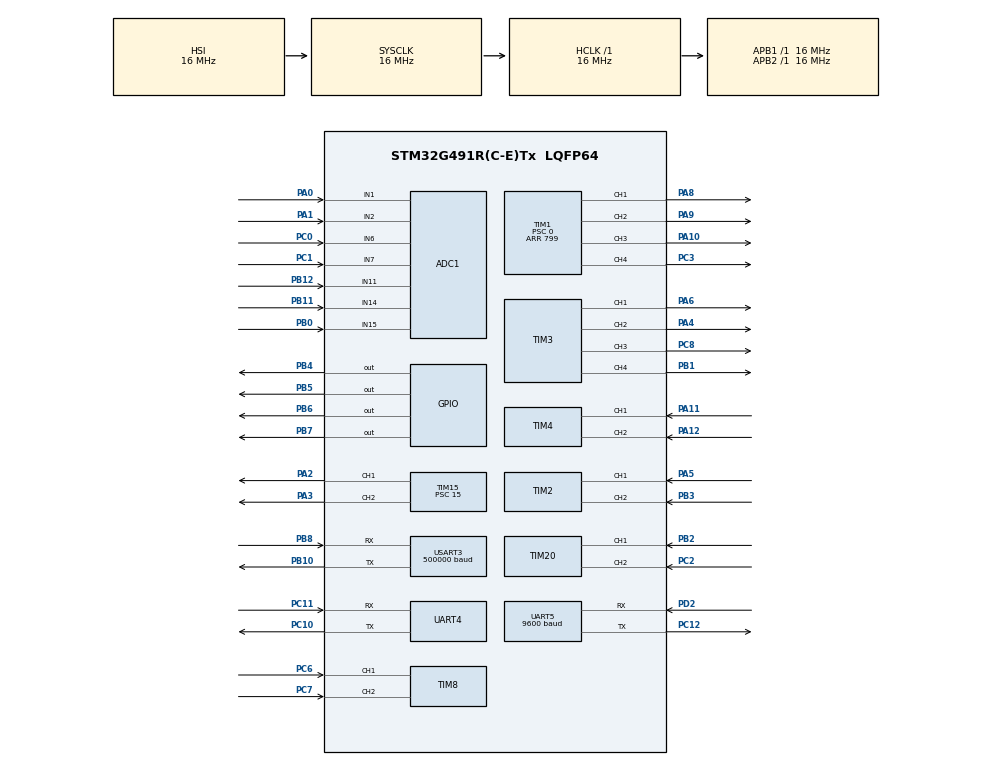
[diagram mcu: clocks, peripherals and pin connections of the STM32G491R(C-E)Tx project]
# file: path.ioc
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ADC1.Channel-1\#ChannelRegularConversion=ADC_CHANNEL_1
ADC1.Channel-2\#ChannelRegularConversion=ADC_CHANNEL_2
ADC1.Channel-3\#ChannelRegularConversion=ADC_CHANNEL_15
ADC1.Channel-4\#ChannelRegularConversion=ADC_CHANNEL_7
ADC1.Channel-5\#ChannelRegularConversion=ADC_CHANNEL_6
ADC1.Channel-6\#ChannelRegularConversion=ADC_CHANNEL_11
ADC1.Channel-7\#ChannelRegularConversion=ADC_CHANNEL_14
ADC1.ContinuousConvMode=ENABLE
ADC1.DMAContinuousRequests=ENABLE
ADC1.NbrOfConversion=7
ADC1.NbrOfConversionFlag=1
ADC1.OffsetNumber-1\#ChannelRegularConversion=ADC_OFFSET_NONE
ADC1.OffsetNumber-2\#ChannelRegularConversion=ADC_OFFSET_NONE
ADC1.OffsetNumber-3\#ChannelRegularConversion=ADC_OFFSET_NONE
ADC1.OffsetNumber-4\#ChannelRegularConversion=ADC_OFFSET_NONE
ADC1.OffsetNumber-5\#ChannelRegularConversion=ADC_OFFSET_NONE
ADC1.OffsetNumber-6\#ChannelRegularConversion=ADC_OFFSET_NONE
ADC1.OffsetNumber-7\#ChannelRegularConversion=ADC_OFFSET_NONE
ADC1.Rank-1\#ChannelRegularConversion=1
ADC1.Rank-2\#ChannelRegularConversion=2
ADC1.Rank-3\#ChannelRegularConversion=3
ADC1.Rank-4\#ChannelRegularConversion=4
ADC1.Rank-5\#ChannelRegularConversion=5
ADC1.Rank-6\#ChannelRegularConversion=6
ADC1.Rank-7\#ChannelRegularConversion=7
ADC1.SamplingTime-1\#ChannelRegularConversion=ADC_SAMPLETIME_92CYCLES_5
ADC1.SamplingTime-2\#ChannelRegularConversion=ADC_SAMPLETIME_92CYCLES_5
ADC1.SamplingTime-3\#ChannelRegularConversion=ADC_SAMPLETIME_92CYCLES_5
ADC1.SamplingTime-4\#ChannelRegularConversion=ADC_SAMPLETIME_92CYCLES_5
ADC1.SamplingTime-5\#ChannelRegularConversion=ADC_SAMPLETIME_92CYCLES_5
ADC1.SamplingTime-6\#ChannelRegularConversion=ADC_SAMPLETIME_92CYCLES_5
ADC1.SamplingTime-7\#ChannelRegularConversion=ADC_SAMPLETIME_92CYCLES_5
ADC1.master=1
Dma.ADC1.0.Direction=DMA_PERIPH_TO_MEMORY
Dma.ADC1.0.EventEnable=DISABLE
Dma.ADC1.0.Instance=DMA1_Channel3
Dma.ADC1.0.MemDataAlignment=DMA_MDATAALIGN_HALFWORD
Dma.ADC1.0.MemInc=DMA_MINC_ENABLE
Dma.ADC1.0.Mode=DMA_CIRCULAR
Dma.ADC1.0.PeriphDataAlignment=DMA_PDATAALIGN_HALFWORD
Dma.ADC1.0.PeriphInc=DMA_PINC_DISABLE
Dma.ADC1.0.Polarity=HAL_DMAMUX_REQ_GEN_RISING
Dma.ADC1.0.Priority=DMA_PRIORITY_LOW
Dma.ADC1.0.RequestNumber=1
Dma.ADC1.0.SignalID=NONE
Dma.ADC1.0.SyncEnable=DISABLE
Dma.ADC1.0.SyncPolarity=HAL_DMAMUX_SYNC_NO_EVENT
Dma.ADC1.0.SyncRequestNumber=1
Dma.ADC1.0.SyncSignalID=NONE
Dma.Request0=ADC1
Mcu.Family=STM32G4
Mcu.Name=STM32G491R(C-E)Tx
Mcu.Package=LQFP64
NVIC.DMA1_Channel3_IRQn=true\:0\:0\:false\:false\:true\:false\:true\:true
NVIC.PriorityGroup=NVIC_PRIORITYGROUP_4
NVIC.TIM1_BRK_TIM15_IRQn=true\:0\:0\:false\:false\:true\:true\:true\:true
NVIC.TIM3_IRQn=true\:0\:0\:false\:false\:true\:true\:true\:true
NVIC.TIM6_DAC_IRQn=true\:0\:0\:false\:false\:true\:true\:true\:true
NVIC.UART5_IRQn=true\:0\:0\:false\:false\:true\:true\:true\:true
PA0.Mode=IN1-Single-Ended
PA0.Signal=ADC1_IN1
PA1.Mode=IN2-Single-Ended
PA1.Signal=ADC1_IN2
PA10.Signal=S_TIM1_CH3
PA11.Signal=S_TIM4_CH1
PA12.Signal=S_TIM4_CH2
PA2.Signal=S_TIM15_CH1
PA3.Signal=S_TIM15_CH2
PA4.Signal=S_TIM3_CH2
PA5.Signal=S_TIM2_CH1
PA6.Signal=S_TIM3_CH1
PA8.Signal=S_TIM1_CH1
PA9.Signal=S_TIM1_CH2
PB0.Mode=IN15-Single-Ended
PB0.Signal=ADC1_IN15
PB1.Signal=S_TIM3_CH4
PB10.Mode=Asynchronous
PB10.Signal=USART3_TX
PB11.Mode=IN14-Single-Ended
PB11.Signal=ADC1_IN14
PB12.Mode=IN11-Single-Ended
PB12.Signal=ADC1_IN11
PB2.Mode=Encoder_Interface
PB2.Signal=TIM20_CH1
PB3.Signal=S_TIM2_CH2
PB4.Signal=GPIO_Output
PB5.Signal=GPIO_Output
PB6.Signal=GPIO_Output
PB7.Signal=GPIO_Output
PB8-BOOT0.Mode=Asynchronous
PB8-BOOT0.Signal=USART3_RX
PC0.Mode=IN6-Single-Ended
PC0.Signal=ADC1_IN6
PC1.Mode=IN7-Single-Ended
PC1.Signal=ADC1_IN7
PC10.Mode=Asynchronous
PC10.Signal=UART4_TX
PC11.Mode=Asynchronous
PC11.Signal=UART4_RX
PC12.Mode=Asynchronous
PC12.Signal=UART5_TX
PC2.Signal=S_TIM20_CH2
PC3.Signal=S_TIM1_CH4
PC6.Signal=S_TIM8_CH1
PC7.Signal=S_TIM8_CH2
PC8.Signal=S_TIM3_CH3
PD2.Mode=Asynchronous
PD2.Signal=UART5_RX
ProjectManager.HeapSize=0x200
ProjectManager.StackSize=0x400
ProjectManager.TargetToolchain=STM32CubeIDE
RCC.ADC12Freq_Value=16000000
RCC.ADC345Freq_Value=16000000
RCC.AHBFreq_Value=16000000
RCC.APB1Freq_Value=16000000
RCC.APB1TimFreq_Value=16000000
RCC.APB2Freq_Value=16000000
RCC.APB2TimFreq_Value=16000000
RCC.CortexFreq_Value=16000000
RCC.EXTERNAL_CLOCK_VALUE=12288000
RCC.HCLKFreq_Value=16000000
RCC.HSE_VALUE=8000000
RCC.HSI48_VALUE=48000000
RCC.HSI_VALUE=16000000
RCC.LSE_VALUE=32768
RCC.SYSCLKFreq_VALUE=16000000
RCC.USBFreq_Value=48000000
RCC.VCOOutputFreq_Value=128000000
SH.S_TIM15_CH1.0=TIM15_CH1,PWM Generation1 CH1
SH.S_TIM15_CH2.0=TIM15_CH2,PWM Generation2 CH2
SH.S_TIM1_CH1.0=TIM1_CH1,PWM Generation1 CH1
SH.S_TIM1_CH2.0=TIM1_CH2,PWM Generation2 CH2
SH.S_TIM1_CH3.0=TIM1_CH3,PWM Generation3 CH3
SH.S_TIM1_CH4.0=TIM1_CH4,PWM Generation4 CH4
SH.S_TIM20_CH2.0=TIM20_CH2,Encoder_Interface
SH.S_TIM2_CH1.0=TIM2_CH1,Encoder_Interface
SH.S_TIM2_CH2.0=TIM2_CH2,Encoder_Interface
SH.S_TIM3_CH1.0=TIM3_CH1,PWM Generation1 CH1
SH.S_TIM3_CH2.0=TIM3_CH2,PWM Generation2 CH2
SH.S_TIM3_CH3.0=TIM3_CH3,PWM Generation3 CH3
SH.S_TIM3_CH4.0=TIM3_CH4,PWM Generation4 CH4
SH.S_TIM4_CH1.0=TIM4_CH1,Encoder_Interface
SH.S_TIM4_CH2.0=TIM4_CH2,Encoder_Interface
SH.S_TIM8_CH1.0=TIM8_CH1,Encoder_Interface
SH.S_TIM8_CH2.0=TIM8_CH2,Encoder_Interface
TIM1.Channel-PWM\ Generation1\ CH1=TIM_CHANNEL_1
TIM1.Channel-PWM\ Generation2\ CH2=TIM_CHANNEL_2
TIM1.Channel-PWM\ Generation3\ CH3=TIM_CHANNEL_3
TIM1.Channel-PWM\ Generation4\ CH4=TIM_CHANNEL_4
TIM1.PeriodNoDither=799
TIM1.Prescaler=0
TIM15.Channel-PWM\ Generation1\ CH1=TIM_CHANNEL_1
TIM15.Channel-PWM\ Generation2\ CH2=TIM_CHANNEL_2
TIM15.PeriodNoDither=19999
TIM15.Prescaler=15
TIM3.Channel-PWM\ Generation1\ CH1=TIM_CHANNEL_1
TIM3.Channel-PWM\ Generation2\ CH2=TIM_CHANNEL_2
TIM3.Channel-PWM\ Generation3\ CH3=TIM_CHANNEL_3
TIM3.Channel-PWM\ Generation4\ CH4=TIM_CHANNEL_4
TIM6.PeriodNoDither=999
TIM6.Prescaler=15
TIM8.EncoderMode=TIM_ENCODERMODE_TI12
UART5.BaudRate=9600
USART3.BaudRate=500000
USART3.VirtualMode-Asynchronous=VM_ASYNC
VP_TIM16_VS_ClockSourceINT.Mode=Enable_Timer
VP_TIM6_VS_ClockSourceINT.Mode=Enable_Timer
board=custom

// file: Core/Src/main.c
/* USER CODE BEGIN Header */
/**
  ******************************************************************************
  * @file           : main.c
  * @brief          : Main program body
  ******************************************************************************
  * @attention
  *
  * Copyright (c) 2024 STMicroelectronics.
  * All rights reserved.
  *
  * This software is licensed under terms that can be found in the LICENSE file
  * in the root directory of this software component.
  * If no LICENSE file comes with this software, it is provided AS-IS.
  *
  ******************************************************************************
  */
/* USER CODE END Header */
#include "main.h"

/* USER CODE BEGIN Includes */
#include "mainpp.h"
/* USER CODE END Includes */

ADC_HandleTypeDef hadc1;
DMA_HandleTypeDef hdma_adc1;

TIM_HandleTypeDef htim1;
TIM_HandleTypeDef htim2;
TIM_HandleTypeDef htim3;
TIM_HandleTypeDef htim4;
TIM_HandleTypeDef htim6;
TIM_HandleTypeDef htim8;
TIM_HandleTypeDef htim15;
TIM_HandleTypeDef htim16;
TIM_HandleTypeDef htim20;

UART_HandleTypeDef huart4;
UART_HandleTypeDef huart5;
UART_HandleTypeDef huart3;

void SystemClock_Config(void);
static void MX_GPIO_Init(void);
static void MX_DMA_Init(void);
static void MX_ADC1_Init(void);
static void MX_TIM6_Init(void);
static void MX_TIM15_Init(void);
static void MX_TIM4_Init(void);
static void MX_UART5_Init(void);
static void MX_TIM3_Init(void);
static void MX_TIM1_Init(void);
static void MX_TIM8_Init(void);
static void MX_TIM16_Init(void);
static void MX_TIM20_Init(void);
static void MX_UART4_Init(void);
static void MX_USART3_UART_Init(void);
static void MX_TIM2_Init(void);

int main(void)
{

  /* MCU Configuration--------------------------------------------------------*/

  /* Reset of all peripherals, Initializes the Flash interface and the Systick. */
  HAL_Init();

  /* Configure the system clock */
  SystemClock_Config();

  /* Initialize all configured peripherals */
  MX_GPIO_Init();
  MX_DMA_Init();
  MX_ADC1_Init();
  MX_TIM6_Init();
  MX_TIM15_Init();
  MX_TIM4_Init();
  MX_UART5_Init();
  MX_TIM3_Init();
  MX_TIM1_Init();
  MX_TIM8_Init();
  MX_TIM16_Init();
  MX_TIM20_Init();
  MX_UART4_Init();
  MX_USART3_UART_Init();
  MX_TIM2_Init();
  /* USER CODE BEGIN 2 */
  //
  setup();
  /* USER CODE END 2 */

  /* Infinite loop */
  /* USER CODE BEGIN WHILE */
  while (1)
  {main_function();
    /* USER CODE END WHILE */

  }
}

void SystemClock_Config(void)
{
  RCC_OscInitTypeDef RCC_OscInitStruct = {0};
  RCC_ClkInitTypeDef RCC_ClkInitStruct = {0};

  /** Configure the main internal regulator output voltage
  */
  HAL_PWREx_ControlVoltageScaling(PWR_REGULATOR_VOLTAGE_SCALE1);

  /** Initializes the RCC Oscillators according to the specified parameters
  * in the RCC_OscInitTypeDef structure.
  */
  RCC_OscInitStruct.OscillatorType = RCC_OSCILLATORTYPE_HSI;
  RCC_OscInitStruct.HSIState = RCC_HSI_ON;
  RCC_OscInitStruct.HSICalibrationValue = RCC_HSICALIBRATION_DEFAULT;
  RCC_OscInitStruct.PLL.PLLState = RCC_PLL_NONE;
  if (HAL_RCC_OscConfig(&RCC_OscInitStruct) != HAL_OK)
  {
    Error_Handler();
  }

  /** Initializes the CPU, AHB and APB buses clocks
  */
  RCC_ClkInitStruct.ClockType = RCC_CLOCKTYPE_HCLK|RCC_CLOCKTYPE_SYSCLK
                              |RCC_CLOCKTYPE_PCLK1|RCC_CLOCKTYPE_PCLK2;
  RCC_ClkInitStruct.SYSCLKSource = RCC_SYSCLKSOURCE_HSI;
  RCC_ClkInitStruct.AHBCLKDivider = RCC_SYSCLK_DIV1;
  RCC_ClkInitStruct.APB1CLKDivider = RCC_HCLK_DIV1;
  RCC_ClkInitStruct.APB2CLKDivider = RCC_HCLK_DIV1;

  if (HAL_RCC_ClockConfig(&RCC_ClkInitStruct, FLASH_LATENCY_0) != HAL_OK)
  {
    Error_Handler();
  }
}

static void MX_ADC1_Init(void)
{

  ADC_MultiModeTypeDef multimode = {0};
  ADC_ChannelConfTypeDef sConfig = {0};

  /** Common config
  */
  hadc1.Instance = ADC1;
  hadc1.Init.ClockPrescaler = ADC_CLOCK_SYNC_PCLK_DIV2;
  hadc1.Init.Resolution = ADC_RESOLUTION_12B;
  hadc1.Init.DataAlign = ADC_DATAALIGN_RIGHT;
  hadc1.Init.GainCompensation = 0;
  hadc1.Init.ScanConvMode = ADC_SCAN_ENABLE;
  hadc1.Init.EOCSelection = ADC_EOC_SINGLE_CONV;
  hadc1.Init.LowPowerAutoWait = DISABLE;
  hadc1.Init.ContinuousConvMode = ENABLE;
  hadc1.Init.NbrOfConversion = 7;
  hadc1.Init.DiscontinuousConvMode = DISABLE;
  hadc1.Init.ExternalTrigConv = ADC_SOFTWARE_START;
  hadc1.Init.ExternalTrigConvEdge = ADC_EXTERNALTRIGCONVEDGE_NONE;
  hadc1.Init.DMAContinuousRequests = ENABLE;
  hadc1.Init.Overrun = ADC_OVR_DATA_PRESERVED;
  hadc1.Init.OversamplingMode = DISABLE;
  if (HAL_ADC_Init(&hadc1) != HAL_OK)
  {
    Error_Handler();
  }

  /** Configure the ADC multi-mode
  */
  multimode.Mode = ADC_MODE_INDEPENDENT;
  if (HAL_ADCEx_MultiModeConfigChannel(&hadc1, &multimode) != HAL_OK)
  {
    Error_Handler();
  }

  /** Configure Regular Channel
  */
  sConfig.Channel = ADC_CHANNEL_1;
  sConfig.Rank = ADC_REGULAR_RANK_1;
  sConfig.SamplingTime = ADC_SAMPLETIME_92CYCLES_5;
  sConfig.SingleDiff = ADC_SINGLE_ENDED;
  sConfig.OffsetNumber = ADC_OFFSET_NONE;
  sConfig.Offset = 0;
  if (HAL_ADC_ConfigChannel(&hadc1, &sConfig) != HAL_OK)
  {
    Error_Handler();
  }

  /** Configure Regular Channel
  */
  sConfig.Channel = ADC_CHANNEL_2;
  sConfig.Rank = ADC_REGULAR_RANK_2;
  if (HAL_ADC_ConfigChannel(&hadc1, &sConfig) != HAL_OK)
  {
    Error_Handler();
  }

  /** Configure Regular Channel
  */
  sConfig.Channel = ADC_CHANNEL_15;
  sConfig.Rank = ADC_REGULAR_RANK_3;
  if (HAL_ADC_ConfigChannel(&hadc1, &sConfig) != HAL_OK)
  {
    Error_Handler();
  }

  /** Configure Regular Channel
  */
  sConfig.Channel = ADC_CHANNEL_7;
  sConfig.Rank = ADC_REGULAR_RANK_4;
  if (HAL_ADC_ConfigChannel(&hadc1, &sConfig) != HAL_OK)
  {
    Error_Handler();
  }

  /** Configure Regular Channel
  */
  sConfig.Channel = ADC_CHANNEL_6;
  sConfig.Rank = ADC_REGULAR_RANK_5;
  if (HAL_ADC_ConfigChannel(&hadc1, &sConfig) != HAL_OK)
  {
    Error_Handler();
  }

  /** Configure Regular Channel
  */
  sConfig.Channel = ADC_CHANNEL_11;
  sConfig.Rank = ADC_REGULAR_RANK_6;
  if (HAL_ADC_ConfigChannel(&hadc1, &sConfig) != HAL_OK)
  {
    Error_Handler();
  }

  /** Configure Regular Channel
  */
  sConfig.Channel = ADC_CHANNEL_14;
  sConfig.Rank = ADC_REGULAR_RANK_7;
  if (HAL_ADC_ConfigChannel(&hadc1, &sConfig) != HAL_OK)
  {
    Error_Handler();
  }

}

static void MX_TIM1_Init(void)
{

  TIM_MasterConfigTypeDef sMasterConfig = {0};
  TIM_OC_InitTypeDef sConfigOC = {0};
  TIM_BreakDeadTimeConfigTypeDef sBreakDeadTimeConfig = {0};

  htim1.Instance = TIM1;
  htim1.Init.Prescaler = 0;
  htim1.Init.CounterMode = TIM_COUNTERMODE_UP;
  htim1.Init.Period = 799;
  htim1.Init.ClockDivision = TIM_CLOCKDIVISION_DIV1;
  htim1.Init.RepetitionCounter = 0;
  htim1.Init.AutoReloadPreload = TIM_AUTORELOAD_PRELOAD_DISABLE;
  if (HAL_TIM_PWM_Init(&htim1) != HAL_OK)
  {
    Error_Handler();
  }
  sMasterConfig.MasterOutputTrigger = TIM_TRGO_RESET;
  sMasterConfig.MasterOutputTrigger2 = TIM_TRGO2_RESET;
  sMasterConfig.MasterSlaveMode = TIM_MASTERSLAVEMODE_DISABLE;
  if (HAL_TIMEx_MasterConfigSynchronization(&htim1, &sMasterConfig) != HAL_OK)
  {
    Error_Handler();
  }
  sConfigOC.OCMode = TIM_OCMODE_PWM1;
  sConfigOC.Pulse = 0;
  sConfigOC.OCPolarity = TIM_OCPOLARITY_HIGH;
  sConfigOC.OCNPolarity = TIM_OCNPOLARITY_HIGH;
  sConfigOC.OCFastMode = TIM_OCFAST_DISABLE;
  sConfigOC.OCIdleState = TIM_OCIDLESTATE_RESET;
  sConfigOC.OCNIdleState = TIM_OCNIDLESTATE_RESET;
  if (HAL_TIM_PWM_ConfigChannel(&htim1, &sConfigOC, TIM_CHANNEL_1) != HAL_OK)
  {
    Error_Handler();
  }
  if (HAL_TIM_PWM_ConfigChannel(&htim1, &sConfigOC, TIM_CHANNEL_2) != HAL_OK)
  {
    Error_Handler();
  }
  if (HAL_TIM_PWM_ConfigChannel(&htim1, &sConfigOC, TIM_CHANNEL_3) != HAL_OK)
  {
    Error_Handler();
  }
  if (HAL_TIM_PWM_ConfigChannel(&htim1, &sConfigOC, TIM_CHANNEL_4) != HAL_OK)
  {
    Error_Handler();
  }
  sBreakDeadTimeConfig.OffStateRunMode = TIM_OSSR_DISABLE;
  sBreakDeadTimeConfig.OffStateIDLEMode = TIM_OSSI_DISABLE;
  sBreakDeadTimeConfig.LockLevel = TIM_LOCKLEVEL_OFF;
  sBreakDeadTimeConfig.DeadTime = 0;
  sBreakDeadTimeConfig.BreakState = TIM_BREAK_DISABLE;
  sBreakDeadTimeConfig.BreakPolarity = TIM_BREAKPOLARITY_HIGH;
  sBreakDeadTimeConfig.BreakFilter = 0;
  sBreakDeadTimeConfig.BreakAFMode = TIM_BREAK_AFMODE_INPUT;
  sBreakDeadTimeConfig.Break2State = TIM_BREAK2_DISABLE;
  sBreakDeadTimeConfig.Break2Polarity = TIM_BREAK2POLARITY_HIGH;
  sBreakDeadTimeConfig.Break2Filter = 0;
  sBreakDeadTimeConfig.Break2AFMode = TIM_BREAK_AFMODE_INPUT;
  sBreakDeadTimeConfig.AutomaticOutput = TIM_AUTOMATICOUTPUT_DISABLE;
  if (HAL_TIMEx_ConfigBreakDeadTime(&htim1, &sBreakDeadTimeConfig) != HAL_OK)
  {
    Error_Handler();
  }
  HAL_TIM_MspPostInit(&htim1);

}

static void MX_TIM2_Init(void)
{

  TIM_Encoder_InitTypeDef sConfig = {0};
  TIM_MasterConfigTypeDef sMasterConfig = {0};

  htim2.Instance = TIM2;
  htim2.Init.Prescaler = 0;
  htim2.Init.CounterMode = TIM_COUNTERMODE_UP;
  htim2.Init.Period = 4.294967295E9;
  htim2.Init.ClockDivision = TIM_CLOCKDIVISION_DIV1;
  htim2.Init.AutoReloadPreload = TIM_AUTORELOAD_PRELOAD_DISABLE;
  sConfig.EncoderMode = TIM_ENCODERMODE_TI1;
  sConfig.IC1Polarity = TIM_ICPOLARITY_RISING;
  sConfig.IC1Selection = TIM_ICSELECTION_DIRECTTI;
  sConfig.IC1Prescaler = TIM_ICPSC_DIV1;
  sConfig.IC1Filter = 0;
  sConfig.IC2Polarity = TIM_ICPOLARITY_RISING;
  sConfig.IC2Selection = TIM_ICSELECTION_DIRECTTI;
  sConfig.IC2Prescaler = TIM_ICPSC_DIV1;
  sConfig.IC2Filter = 0;
  if (HAL_TIM_Encoder_Init(&htim2, &sConfig) != HAL_OK)
  {
    Error_Handler();
  }
  sMasterConfig.MasterOutputTrigger = TIM_TRGO_RESET;
  sMasterConfig.MasterSlaveMode = TIM_MASTERSLAVEMODE_DISABLE;
  if (HAL_TIMEx_MasterConfigSynchronization(&htim2, &sMasterConfig) != HAL_OK)
  {
    Error_Handler();
  }

}

static void MX_TIM3_Init(void)
{

  TIM_MasterConfigTypeDef sMasterConfig = {0};
  TIM_OC_InitTypeDef sConfigOC = {0};

  htim3.Instance = TIM3;
  htim3.Init.Prescaler = 0;
  htim3.Init.CounterMode = TIM_COUNTERMODE_UP;
  htim3.Init.Period = 65535;
  htim3.Init.ClockDivision = TIM_CLOCKDIVISION_DIV1;
  htim3.Init.AutoReloadPreload = TIM_AUTORELOAD_PRELOAD_DISABLE;
  if (HAL_TIM_PWM_Init(&htim3) != HAL_OK)
  {
    Error_Handler();
  }
  sMasterConfig.MasterOutputTrigger = TIM_TRGO_RESET;
  sMasterConfig.MasterSlaveMode = TIM_MASTERSLAVEMODE_DISABLE;
  if (HAL_TIMEx_MasterConfigSynchronization(&htim3, &sMasterConfig) != HAL_OK)
  {
    Error_Handler();
  }
  sConfigOC.OCMode = TIM_OCMODE_PWM1;
  sConfigOC.Pulse = 0;
  sConfigOC.OCPolarity = TIM_OCPOLARITY_HIGH;
  sConfigOC.OCFastMode = TIM_OCFAST_DISABLE;
  if (HAL_TIM_PWM_ConfigChannel(&htim3, &sConfigOC, TIM_CHANNEL_1) != HAL_OK)
  {
    Error_Handler();
  }
  if (HAL_TIM_PWM_ConfigChannel(&htim3, &sConfigOC, TIM_CHANNEL_2) != HAL_OK)
  {
    Error_Handler();
  }
  if (HAL_TIM_PWM_ConfigChannel(&htim3, &sConfigOC, TIM_CHANNEL_3) != HAL_OK)
  {
    Error_Handler();
  }
  if (HAL_TIM_PWM_ConfigChannel(&htim3, &sConfigOC, TIM_CHANNEL_4) != HAL_OK)
  {
    Error_Handler();
  }
  HAL_TIM_MspPostInit(&htim3);

}

static void MX_TIM4_Init(void)
{

  TIM_Encoder_InitTypeDef sConfig = {0};
  TIM_MasterConfigTypeDef sMasterConfig = {0};

  htim4.Instance = TIM4;
  htim4.Init.Prescaler = 0;
  htim4.Init.CounterMode = TIM_COUNTERMODE_UP;
  htim4.Init.Period = 65535;
  htim4.Init.ClockDivision = TIM_CLOCKDIVISION_DIV1;
  htim4.Init.AutoReloadPreload = TIM_AUTORELOAD_PRELOAD_DISABLE;
  sConfig.EncoderMode = TIM_ENCODERMODE_TI1;
  sConfig.IC1Polarity = TIM_ICPOLARITY_RISING;
  sConfig.IC1Selection = TIM_ICSELECTION_DIRECTTI;
  sConfig.IC1Prescaler = TIM_ICPSC_DIV1;
  sConfig.IC1Filter = 0;
  sConfig.IC2Polarity = TIM_ICPOLARITY_RISING;
  sConfig.IC2Selection = TIM_ICSELECTION_DIRECTTI;
  sConfig.IC2Prescaler = TIM_ICPSC_DIV1;
  sConfig.IC2Filter = 0;
  if (HAL_TIM_Encoder_Init(&htim4, &sConfig) != HAL_OK)
  {
    Error_Handler();
  }
  sMasterConfig.MasterOutputTrigger = TIM_TRGO_RESET;
  sMasterConfig.MasterSlaveMode = TIM_MASTERSLAVEMODE_DISABLE;
  if (HAL_TIMEx_MasterConfigSynchronization(&htim4, &sMasterConfig) != HAL_OK)
  {
    Error_Handler();
  }

}

static void MX_TIM6_Init(void)
{

  TIM_MasterConfigTypeDef sMasterConfig = {0};

  htim6.Instance = TIM6;
  htim6.Init.Prescaler = 15;
  htim6.Init.CounterMode = TIM_COUNTERMODE_UP;
  htim6.Init.Period = 999;
  htim6.Init.AutoReloadPreload = TIM_AUTORELOAD_PRELOAD_DISABLE;
  if (HAL_TIM_Base_Init(&htim6) != HAL_OK)
  {
    Error_Handler();
  }
  sMasterConfig.MasterOutputTrigger = TIM_TRGO_RESET;
  sMasterConfig.MasterSlaveMode = TIM_MASTERSLAVEMODE_DISABLE;
  if (HAL_TIMEx_MasterConfigSynchronization(&htim6, &sMasterConfig) != HAL_OK)
  {
    Error_Handler();
  }

}

static void MX_TIM8_Init(void)
{

  TIM_Encoder_InitTypeDef sConfig = {0};
  TIM_MasterConfigTypeDef sMasterConfig = {0};

  htim8.Instance = TIM8;
  htim8.Init.Prescaler = 0;
  htim8.Init.CounterMode = TIM_COUNTERMODE_UP;
  htim8.Init.Period = 65535;
  htim8.Init.ClockDivision = TIM_CLOCKDIVISION_DIV1;
  htim8.Init.RepetitionCounter = 0;
  htim8.Init.AutoReloadPreload = TIM_AUTORELOAD_PRELOAD_DISABLE;
  sConfig.EncoderMode = TIM_ENCODERMODE_TI12;
  sConfig.IC1Polarity = TIM_ICPOLARITY_RISING;
  sConfig.IC1Selection = TIM_ICSELECTION_DIRECTTI;
  sConfig.IC1Prescaler = TIM_ICPSC_DIV1;
  sConfig.IC1Filter = 0;
  sConfig.IC2Polarity = TIM_ICPOLARITY_RISING;
  sConfig.IC2Selection = TIM_ICSELECTION_DIRECTTI;
  sConfig.IC2Prescaler = TIM_ICPSC_DIV1;
  sConfig.IC2Filter = 0;
  if (HAL_TIM_Encoder_Init(&htim8, &sConfig) != HAL_OK)
  {
    Error_Handler();
  }
  sMasterConfig.MasterOutputTrigger = TIM_TRGO_RESET;
  sMasterConfig.MasterOutputTrigger2 = TIM_TRGO2_RESET;
  sMasterConfig.MasterSlaveMode = TIM_MASTERSLAVEMODE_DISABLE;
  if (HAL_TIMEx_MasterConfigSynchronization(&htim8, &sMasterConfig) != HAL_OK)
  {
    Error_Handler();
  }

}

static void MX_TIM15_Init(void)
{

  TIM_MasterConfigTypeDef sMasterConfig = {0};
  TIM_OC_InitTypeDef sConfigOC = {0};
  TIM_BreakDeadTimeConfigTypeDef sBreakDeadTimeConfig = {0};

  htim15.Instance = TIM15;
  htim15.Init.Prescaler = 15;
  htim15.Init.CounterMode = TIM_COUNTERMODE_UP;
  htim15.Init.Period = 19999;
  htim15.Init.ClockDivision = TIM_CLOCKDIVISION_DIV1;
  htim15.Init.RepetitionCounter = 0;
  htim15.Init.AutoReloadPreload = TIM_AUTORELOAD_PRELOAD_DISABLE;
  if (HAL_TIM_PWM_Init(&htim15) != HAL_OK)
  {
    Error_Handler();
  }
  sMasterConfig.MasterOutputTrigger = TIM_TRGO_RESET;
  sMasterConfig.MasterSlaveMode = TIM_MASTERSLAVEMODE_DISABLE;
  if (HAL_TIMEx_MasterConfigSynchronization(&htim15, &sMasterConfig) != HAL_OK)
  {
    Error_Handler();
  }
  sConfigOC.OCMode = TIM_OCMODE_PWM1;
  sConfigOC.Pulse = 0;
  sConfigOC.OCPolarity = TIM_OCPOLARITY_HIGH;
  sConfigOC.OCNPolarity = TIM_OCNPOLARITY_HIGH;
  sConfigOC.OCFastMode = TIM_OCFAST_DISABLE;
  sConfigOC.OCIdleState = TIM_OCIDLESTATE_RESET;
  sConfigOC.OCNIdleState = TIM_OCNIDLESTATE_RESET;
  if (HAL_TIM_PWM_ConfigChannel(&htim15, &sConfigOC, TIM_CHANNEL_1) != HAL_OK)
  {
    Error_Handler();
  }
  if (HAL_TIM_PWM_ConfigChannel(&htim15, &sConfigOC, TIM_CHANNEL_2) != HAL_OK)
  {
    Error_Handler();
  }
  sBreakDeadTimeConfig.OffStateRunMode = TIM_OSSR_DISABLE;
  sBreakDeadTimeConfig.OffStateIDLEMode = TIM_OSSI_DISABLE;
  sBreakDeadTimeConfig.LockLevel = TIM_LOCKLEVEL_OFF;
  sBreakDeadTimeConfig.DeadTime = 0;
  sBreakDeadTimeConfig.BreakState = TIM_BREAK_DISABLE;
  sBreakDeadTimeConfig.BreakPolarity = TIM_BREAKPOLARITY_HIGH;
  sBreakDeadTimeConfig.BreakFilter = 0;
  sBreakDeadTimeConfig.AutomaticOutput = TIM_AUTOMATICOUTPUT_DISABLE;
  if (HAL_TIMEx_ConfigBreakDeadTime(&htim15, &sBreakDeadTimeConfig) != HAL_OK)
  {
    Error_Handler();
  }
  HAL_TIM_MspPostInit(&htim15);

}

static void MX_TIM16_Init(void)
{

  htim16.Instance = TIM16;
  htim16.Init.Prescaler = 0;
  htim16.Init.CounterMode = TIM_COUNTERMODE_UP;
  htim16.Init.Period = 65535;
  htim16.Init.ClockDivision = TIM_CLOCKDIVISION_DIV1;
  htim16.Init.RepetitionCounter = 0;
  htim16.Init.AutoReloadPreload = TIM_AUTORELOAD_PRELOAD_DISABLE;
  if (HAL_TIM_Base_Init(&htim16) != HAL_OK)
  {
    Error_Handler();
  }

}

static void MX_TIM20_Init(void)
{

  TIM_Encoder_InitTypeDef sConfig = {0};
  TIM_MasterConfigTypeDef sMasterConfig = {0};

  htim20.Instance = TIM20;
  htim20.Init.Prescaler = 0;
  htim20.Init.CounterMode = TIM_COUNTERMODE_UP;
  htim20.Init.Period = 65535;
  htim20.Init.ClockDivision = TIM_CLOCKDIVISION_DIV1;
  htim20.Init.RepetitionCounter = 0;
  htim20.Init.AutoReloadPreload = TIM_AUTORELOAD_PRELOAD_DISABLE;
  sConfig.EncoderMode = TIM_ENCODERMODE_TI1;
  sConfig.IC1Polarity = TIM_ICPOLARITY_RISING;
  sConfig.IC1Selection = TIM_ICSELECTION_DIRECTTI;
  sConfig.IC1Prescaler = TIM_ICPSC_DIV1;
  sConfig.IC1Filter = 0;
  sConfig.IC2Polarity = TIM_ICPOLARITY_RISING;
  sConfig.IC2Selection = TIM_ICSELECTION_DIRECTTI;
  sConfig.IC2Prescaler = TIM_ICPSC_DIV1;
  sConfig.IC2Filter = 0;
  if (HAL_TIM_Encoder_Init(&htim20, &sConfig) != HAL_OK)
  {
    Error_Handler();
  }
  sMasterConfig.MasterOutputTrigger = TIM_TRGO_RESET;
  sMasterConfig.MasterOutputTrigger2 = TIM_TRGO2_RESET;
  sMasterConfig.MasterSlaveMode = TIM_MASTERSLAVEMODE_DISABLE;
  if (HAL_TIMEx_MasterConfigSynchronization(&htim20, &sMasterConfig) != HAL_OK)
  {
    Error_Handler();
  }

}

static void MX_UART4_Init(void)
{

  huart4.Instance = UART4;
  huart4.Init.BaudRate = 115200;
  huart4.Init.WordLength = UART_WORDLENGTH_8B;
  huart4.Init.StopBits = UART_STOPBITS_1;
  huart4.Init.Parity = UART_PARITY_NONE;
  huart4.Init.Mode = UART_MODE_TX_RX;
  huart4.Init.HwFlowCtl = UART_HWCONTROL_NONE;
  huart4.Init.OverSampling = UART_OVERSAMPLING_16;
  huart4.Init.OneBitSampling = UART_ONE_BIT_SAMPLE_DISABLE;
  huart4.Init.ClockPrescaler = UART_PRESCALER_DIV1;
  huart4.AdvancedInit.AdvFeatureInit = UART_ADVFEATURE_NO_INIT;
  if (HAL_UART_Init(&huart4) != HAL_OK)
  {
    Error_Handler();
  }
  if (HAL_UARTEx_SetTxFifoThreshold(&huart4, UART_TXFIFO_THRESHOLD_1_8) != HAL_OK)
  {
    Error_Handler();
  }
  if (HAL_UARTEx_SetRxFifoThreshold(&huart4, UART_RXFIFO_THRESHOLD_1_8) != HAL_OK)
  {
    Error_Handler();
  }
  if (HAL_UARTEx_DisableFifoMode(&huart4) != HAL_OK)
  {
    Error_Handler();
  }

}

static void MX_UART5_Init(void)
{

  huart5.Instance = UART5;
  huart5.Init.BaudRate = 9600;
  huart5.Init.WordLength = UART_WORDLENGTH_8B;
  huart5.Init.StopBits = UART_STOPBITS_1;
  huart5.Init.Parity = UART_PARITY_NONE;
  huart5.Init.Mode = UART_MODE_TX_RX;
  huart5.Init.HwFlowCtl = UART_HWCONTROL_NONE;
  huart5.Init.OverSampling = UART_OVERSAMPLING_16;
  huart5.Init.OneBitSampling = UART_ONE_BIT_SAMPLE_DISABLE;
  huart5.Init.ClockPrescaler = UART_PRESCALER_DIV1;
  huart5.AdvancedInit.AdvFeatureInit = UART_ADVFEATURE_NO_INIT;
  if (HAL_UART_Init(&huart5) != HAL_OK)
  {
    Error_Handler();
  }
  if (HAL_UARTEx_SetTxFifoThreshold(&huart5, UART_TXFIFO_THRESHOLD_1_8) != HAL_OK)
  {
    Error_Handler();
  }
  if (HAL_UARTEx_SetRxFifoThreshold(&huart5, UART_RXFIFO_THRESHOLD_1_8) != HAL_OK)
  {
    Error_Handler();
  }
  if (HAL_UARTEx_DisableFifoMode(&huart5) != HAL_OK)
  {
    Error_Handler();
  }

}

static void MX_USART3_UART_Init(void)
{

  huart3.Instance = USART3;
  huart3.Init.BaudRate = 500000;
  huart3.Init.WordLength = UART_WORDLENGTH_8B;
  huart3.Init.StopBits = UART_STOPBITS_1;
  huart3.Init.Parity = UART_PARITY_NONE;
  huart3.Init.Mode = UART_MODE_TX_RX;
  huart3.Init.HwFlowCtl = UART_HWCONTROL_NONE;
  huart3.Init.OverSampling = UART_OVERSAMPLING_16;
  huart3.Init.OneBitSampling = UART_ONE_BIT_SAMPLE_DISABLE;
  huart3.Init.ClockPrescaler = UART_PRESCALER_DIV1;
  huart3.AdvancedInit.AdvFeatureInit = UART_ADVFEATURE_NO_INIT;
  if (HAL_UART_Init(&huart3) != HAL_OK)
  {
    Error_Handler();
  }
  if (HAL_UARTEx_SetTxFifoThreshold(&huart3, UART_TXFIFO_THRESHOLD_1_8) != HAL_OK)
  {
    Error_Handler();
  }
  if (HAL_UARTEx_SetRxFifoThreshold(&huart3, UART_RXFIFO_THRESHOLD_1_8) != HAL_OK)
  {
    Error_Handler();
  }
  if (HAL_UARTEx_DisableFifoMode(&huart3) != HAL_OK)
  {
    Error_Handler();
  }

}

static void MX_DMA_Init(void)
{

  /* DMA controller clock enable */
  __HAL_RCC_DMAMUX1_CLK_ENABLE();
  __HAL_RCC_DMA1_CLK_ENABLE();

  /* DMA interrupt init */
  /* DMA1_Channel3_IRQn interrupt configuration */
  HAL_NVIC_SetPriority(DMA1_Channel3_IRQn, 0, 0);
  HAL_NVIC_EnableIRQ(DMA1_Channel3_IRQn);

}

static void MX_GPIO_Init(void)
{
  GPIO_InitTypeDef GPIO_InitStruct = {0};

  /* GPIO Ports Clock Enable */
  __HAL_RCC_GPIOC_CLK_ENABLE();
  __HAL_RCC_GPIOA_CLK_ENABLE();
  __HAL_RCC_GPIOB_CLK_ENABLE();
  __HAL_RCC_GPIOD_CLK_ENABLE();

  /*Configure GPIO pin Output Level */
  HAL_GPIO_WritePin(GPIOB, GPIO_PIN_4|GPIO_PIN_5|GPIO_PIN_6|GPIO_PIN_7, GPIO_PIN_RESET);

  /*Configure GPIO pins : PB4 PB5 PB6 PB7 */
  GPIO_InitStruct.Pin = GPIO_PIN_4|GPIO_PIN_5|GPIO_PIN_6|GPIO_PIN_7;
  GPIO_InitStruct.Mode = GPIO_MODE_OUTPUT_PP;
  GPIO_InitStruct.Pull = GPIO_NOPULL;
  GPIO_InitStruct.Speed = GPIO_SPEED_FREQ_LOW;
  HAL_GPIO_Init(GPIOB, &GPIO_InitStruct);

}

void Error_Handler(void)
{
  __disable_irq();
  while (1)
  {
  }
}
